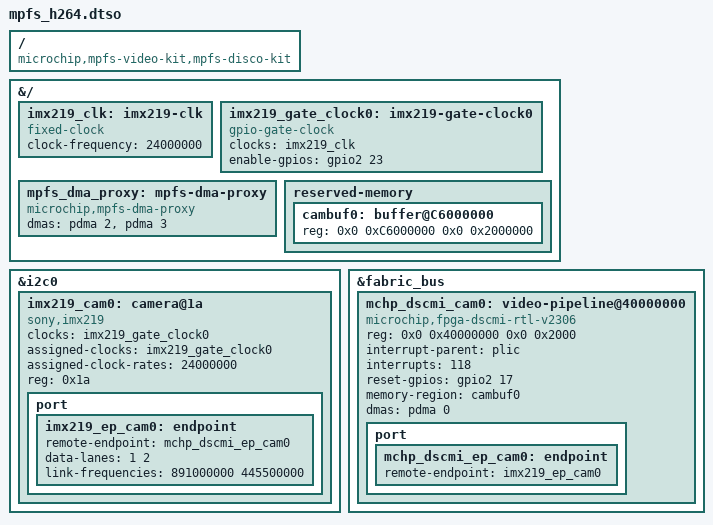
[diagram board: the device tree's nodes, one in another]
// SPDX-License-Identifier: (GPL-2.0+ OR MIT)
/*
 * Device Tree Overlay for H264 pipeline
 *
 * Copyright (C) 2022 Microchip Technology Inc. and its subsidiaries.
 * Author: shrava chippa <shravan.chippa@microchip.com>
 *
 */

/dts-v1/;
/plugin/;

#include <dt-bindings/gpio/gpio.h>

/ {
        compatible = "microchip,mpfs-video-kit,mpfs-disco-kit","microchip,mpfs";
};

&{/} {
	imx219_clk: imx219-clk {
		compatible = "fixed-clock";
		#clock-cells = <0>;
		clock-frequency = <24000000>;
	};

	imx219_gate_clock0: imx219-gate-clock0 {
		compatible = "gpio-gate-clock";
		clocks = <&imx219_clk>;
		#clock-cells = <0>;
		enable-gpios = <&gpio2 23 GPIO_ACTIVE_HIGH>; //Cam__CLK_EN
		status = "okay";
	};

	mpfs_dma_proxy: mpfs-dma-proxy {
		compatible = "microchip,mpfs-dma-proxy";
		dmas = <&pdma 2>, <&pdma 3>;
		dma-names = "dma-proxy0", "dma-proxy1";
	};

	reserved-memory {
		cambuf0: buffer@C6000000 {
			reg = <0x0 0xC6000000 0x0 0x2000000>;
		};
	};
};

&i2c0 {
	imx219_cam0: camera@1a {
		compatible = "sony,imx219";
		clocks = <&imx219_gate_clock0>;
		assigned-clocks = <&imx219_gate_clock0>;
		assigned-clock-rates = <24000000>;
		reg = <0x1a>;
		port {
			imx219_ep_cam0: endpoint {
				remote-endpoint = <&mchp_dscmi_ep_cam0>;
				data-lanes = <1 2>;
				link-frequencies = /bits/ 64 <891000000 445500000>;
			};
		};
	};
};

&fabric_bus {
	#address-cells = <2>;
	#size-cells = <2>;

	mchp_dscmi_cam0: video-pipeline@40000000 {
		compatible = "microchip,fpga-dscmi-rtl-v2306";
		reg = <0x0 0x40000000 0x0 0x2000>;
		interrupt-parent = <&plic>;
		interrupts = <118>;
		reset-gpios = <&gpio2 17 GPIO_ACTIVE_HIGH>;
		memory-region = <&cambuf0>;
		dmas = <&pdma 0>;
		dma-names = "rx";
		port {
			mchp_dscmi_ep_cam0: endpoint {
				remote-endpoint = <&imx219_ep_cam0>;
			};
		};
	};
};

